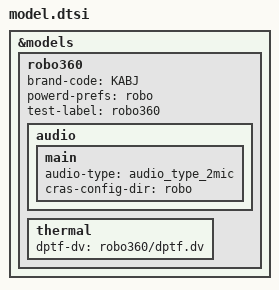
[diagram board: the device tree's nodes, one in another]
/*
 * Copyright 2017 The Chromium OS Authors. All rights reserved.
 *
 * Use of this source code is governed by a BSD-style license that can be
 * found in the LICENSE file.
 */

&models {
	robo360: robo360 {
		brand-code = "KABJ";
		powerd-prefs = "robo";
		test-label = "robo360";
		audio {
			main {
				audio-type = <&audio_type_2mic>;
				cras-config-dir = "robo";
			};
		};
		thermal {
			/* Could also point to robo/dptf.dv */
			dptf-dv = "robo360/dptf.dv";
		};
	};
};
